# platform_designer_hps_system_hps_0_hps register map
Vendor: default_vendor.com; File version: 0.0
Registers are 32-bit, read-write, reset 0x0 unless marked. A register's access mark holds for its fields unless they carry their own. Offsets are from the block's base; [hi:lo] are bit positions; {n}, {i} and the like mark numbered series.

## rstmgr — Registers in the Reset Manager module
Base 0xFFD05000
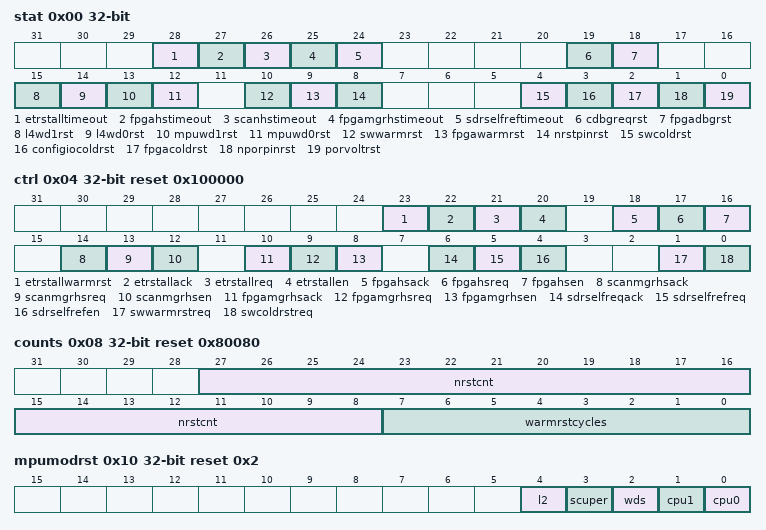
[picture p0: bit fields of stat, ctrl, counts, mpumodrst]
0x00 stat — The STAT register contains bits that indicate the reset source or a timeout event. For reset sources, a field is 1 if its associated reset requester caused the reset. For timeout events, a field is 1 if its associated timeout occured as part of a hardware sequenced warm/debug reset. Software clears bits by writing them with a value of 1. Writes to bits with a value of 0 are ignored. After a cold reset is complete, all bits are reset to their reset value except for the bit(s) that indicate the source of the cold reset. If multiple cold reset requests overlap with each other, the source de-asserts the request last will be logged. The other reset request source(s) de-assert the request in the same cycle will also be logged, the rest of the fields are reset to default value of 0. After a warm reset is complete, the bit(s) that indicate the source of the warm reset are set to 1. A warm reset doesn't clear any of the bits in the STAT register; these bits must be cleared by software writing the STAT register.
  [28] etrstalltimeout write-1-clears — A 1 indicates that Reset Manager's request to the ETR (Embedded Trace Router) to stall its AXI master port before starting a hardware sequenced warm reset timed-out and the Reset Manager had to proceed with the warm reset anyway.
  [27] fpgahstimeout write-1-clears — A 1 indicates that Reset Manager's handshake request to FPGA before starting a hardware sequenced warm reset timed-out and the Reset Manager had to proceed with the warm reset anyway.
  [26] scanhstimeout write-1-clears — A 1 indicates that Reset Manager's request to the SCAN manager to stop driving JTAG clock to FPGA CB before starting a hardware sequenced warm reset timed-out and the Reset Manager had to proceed with the warm reset anyway.
  [25] fpgamgrhstimeout write-1-clears — A 1 indicates that Reset Manager's request to the FPGA manager to stop driving configuration clock to FPGA CB before starting a hardware sequenced warm reset timed-out and the Reset Manager had to proceed with the warm reset anyway.
  [24] sdrselfreftimeout write-1-clears — A 1 indicates that Reset Manager's request to the SDRAM Controller Subsystem to put the SDRAM devices into self-refresh mode before starting a hardware sequenced warm reset timed-out and the Reset Manager had to proceed with the warm reset anyway.
  [19] cdbgreqrst write-1-clears — DAP triggered debug reset
  [18] fpgadbgrst write-1-clears — FPGA triggered debug reset (f2h_dbg_rst_req_n = 1)
  [15] l4wd1rst write-1-clears — L4 Watchdog 1 triggered a hardware sequenced warm reset
  [14] l4wd0rst write-1-clears — L4 Watchdog 0 triggered a hardware sequenced warm reset
  [13] mpuwd1rst write-1-clears — MPU Watchdog 1 triggered a hardware sequenced warm reset
  [12] mpuwd0rst write-1-clears — MPU Watchdog 0 triggered a hardware sequenced warm reset
  [10] swwarmrst write-1-clears — Software wrote CTRL.SWWARMRSTREQ to 1 and triggered a hardware sequenced warm reset
  [9] fpgawarmrst write-1-clears — FPGA core triggered a hardware sequenced warm reset (f2h_warm_rst_req_n = 1)
  [8] nrstpinrst write-1-clears — nRST pin triggered a hardware sequenced warm reset
  [4] swcoldrst write-1-clears — Software wrote CTRL.SWCOLDRSTREQ to 1 and triggered a cold reset
  [3] configiocoldrst write-1-clears — FPGA entered CONFIG_IO mode and a triggered a cold reset
  [2] fpgacoldrst write-1-clears — FPGA core triggered a cold reset (f2h_cold_rst_req_n = 1)
  [1] nporpinrst write-1-clears — nPOR pin triggered a cold reset (por_pin_req = 1)
  [0] porvoltrst write-1-clears — Built-in POR voltage detector triggered a cold reset (por_voltage_req = 1)
0x04 ctrl reset 0x100000 (reset mask 0xFFFBBBFF) — The CTRL register is used by software to control reset behavior.It includes fields for software to initiate the cold and warm reset, enable hardware handshake with other modules before warm reset, and perform software handshake. The software handshake sequence must match the hardware sequence. Software mustde-assert the handshake request after asserting warm reset and before de-assert the warm reset. Fields are only reset by a cold reset.
  [23] etrstallwarmrst write-1-clears — If a warm reset occurs and ETRSTALLEN is 1, hardware sets this bit to 1 to indicate that the stall of the ETR AXI master is pending. Hardware leaves the ETR stalled until software clears this field by writing it with 1. Software must only clear this field when it is ready to have the ETR AXI master start making AXI requests to write trace data.
  [22] etrstallack ro — This is the acknowlege for a ETR AXI master stall initiated by the ETRSTALLREQ field. A 1 indicates that the ETR has stalled its AXI master
  [21] etrstallreq — Software writes this field 1 to request to the ETR that it stalls its AXI master to the L3 Interconnect. Software waits for the ETRSTALLACK to be 1 and then writes this field to 0. Note that it is possible for the ETR to never assert ETRSTALLACK so software should timeout if ETRSTALLACK is never asserted.
  [20] etrstallen — This field controls whether the ETR is requested to idle its AXI master interface (i.e. finish outstanding transactions and not initiate any more) to the L3 Interconnect before a warm or debug reset. If set to 1, the Reset Manager makes a request to the ETR to stall its AXI master and waits for it to finish any outstanding AXI transactions before a warm reset of the L3 Interconnect or a debug reset of the ETR. This stalling is required because the debug logic (including the ETR) is reset on a debug reset and the ETR AXI master is connected to the L3 Interconnect which is reset on a warm reset and these resets can happen independently.
  [18] fpgahsack ro — This is the acknowlege (high active) that the FPGA handshake acknowledge has been received by Reset Manager.
  [17] fpgahsreq — Software writes this field 1 to initiate handshake request to FPGA . Software waits for the FPGAHSACK to be active and then writes this field to 0. Note that it is possible for the FPGA to never assert FPGAHSACK so software should timeout in this case.
  [16] fpgahsen — This field controls whether to perform handshake with FPGA before asserting warm reset. If set to 1, the Reset Manager makes a request to the FPGAbefore asserting warm reset signals. However if FPGA is already in warm reset state, the handshake is not performed. If set to 0, the handshake is not performed
  [14] scanmgrhsack ro — This is the acknowlege (high active) that the SCAN manager has successfully idled its output clocks.
  [13] scanmgrhsreq — Software writes this field 1 to request to the SCAN manager to idle its output clocks. Software waits for the SCANMGRHSACK to be 1 and then writes this field to 0. Note that it is possible for the Scan Manager to never assert SCANMGRHSACK (e.g. its input clock is disabled) so software should timeout in this case.
  [12] scanmgrhsen — Enables a handshake between the Reset Manager and Scan Manager before a warm reset. The handshake is used to warn the Scan Manager that a warm reset it coming so it can prepare for it. When the Scan Manager receives a warm reset handshake, the Scan Manager drives its output clocks to a quiescent state to avoid glitches. If set to 1, the Reset Manager makes a request to the Scan Managerbefore asserting warm reset signals. However if the Scan Manager is already in warm reset, the handshake is skipped. If set to 0, the handshake is skipped.
  [10] fpgamgrhsack ro — This is the acknowlege (high active) that the FPGA manager has successfully idled its output clock.
  [9] fpgamgrhsreq — Software writes this field 1 to request to the FPGA Manager to idle its output clock. Software waits for the FPGAMGRHSACK to be 1 and then writes this field to 0. Note that it is possible for the FPGA Manager to never assert FPGAMGRHSACK so software should timeout in this case.
  [8] fpgamgrhsen — Enables a handshake between the Reset Manager and FPGA Manager before a warm reset. The handshake is used to warn the FPGA Manager that a warm reset it coming so it can prepare for it. When the FPGA Manager receives a warm reset handshake, the FPGA Manager drives its output clock to a quiescent state to avoid glitches. If set to 1, the Manager makes a request to the FPGA Managerbefore asserting warm reset signals. However if the FPGA Manager is already in warm reset, the handshake is skipped. If set to 0, the handshake is skipped.
  [6] sdrselfreqack ro — This is the acknowlege for a SDRAM self-refresh mode request initiated by the SDRSELFREFREQ field. A 1 indicates that the SDRAM Controller Subsystem has put the SDRAM devices into self-refresh mode.
  [5] sdrselfrefreq — Software writes this field 1 to request to the SDRAM Controller Subsystem that it puts the SDRAM devices into self-refresh mode. This is done to preserve SDRAM contents across a software warm reset. Software waits for the SDRSELFREFACK to be 1 and then writes this field to 0. Note that it is possible for the SDRAM Controller Subsystem to never assert SDRSELFREFACK so software should timeout if SDRSELFREFACK is never asserted.
  [4] sdrselfrefen — This field controls whether the contents of SDRAM devices survive a hardware sequenced warm reset. If set to 1, the Reset Manager makes a request to the SDRAM Controller Subsystem to put the SDRAM devices into self-refresh mode before asserting warm reset signals. However, if SDRAM is already in warm reset, Handshake with SDRAM is not performed.
  [1] swwarmrstreq — This is a one-shot bit written by software to 1 to trigger a hardware sequenced warm reset. It always reads the value 0.
  [0] swcoldrstreq — This is a one-shot bit written by software to 1 to trigger a cold reset. It always reads the value 0.
0x08 counts reset 0x80080 — The COUNTS register is used by software to control reset behavior.It includes fields for software to control the behavior of the warm reset and nRST pin. Fields are only reset by a cold reset.
  [27:8] nrstcnt — The Reset Manager pulls down the nRST pin on a warm reset for the number of cycles specified in this register. A value of 0x0 prevents the Reset Manager from pulling down the nRST pin.
  [7:0] warmrstcycles — On a warm reset, the Reset Manager releases the reset to the Clock Manager, and then waits for the number of cycles specified in this register before releasing the rest of the hardware controlled resets. Value must be greater than 16.
0x10 mpumodrst reset 0x2 — The MPUMODRST register is used by software to trigger module resets (individual module reset signals). Software explicitly asserts and de-asserts module reset signals by writing bits in the appropriate *MODRST register. It is up to software to ensure module reset signals are asserted for the appropriate length of time and are de-asserted in the correct order. It is also up to software to not assert a module reset signal that would prevent software from de-asserting the module reset signal. For example, software should not assert the module reset to the CPU executing the software. Software writes a bit to 1 to assert the module reset signal and to 0 to de-assert the module reset signal. All fields except CPU1 are only reset by a cold reset. The CPU1 field is reset by a cold reset. The CPU1 field is also reset by a warm reset if not masked by the corresponding MPUWARMMASK field.
  [4] l2 — Resets L2 cache controller
  [3] scuper — Resets SCU and peripherals. Peripherals consist of the interrupt controller, global timer, both per-CPU private timers, and both per-CPU watchdogs (except for the Watchdog Reset Status registers).
  [2] wds — Resets both per-CPU Watchdog Reset Status registers in MPU.
  [1] cpu1 — Resets Cortex-A9 CPU1 in MPU. It is reset to 1 on a cold or warm reset. This holds CPU1 in reset until software is ready to release CPU1 from reset by writing 0 to this field. On single-core devices, writes to this field are ignored.On dual-core devices, writes to this field trigger the same sequence as writes to the CPU0 field (except the sequence is performed on CPU1).
  [0] cpu0 — Resets Cortex-A9 CPU0 in MPU. Whe software changes this field from 0 to 1, ittriggers the following sequence: 1. CPU0 reset is asserted. cpu0 clkoff is de-asserted 2. after 32 osc1_clk cycles, cpu0 clkoff is asserted. When software changes this field from 1 to 0, it triggers the following sequence: 1.CPU0 reset is de-asserted. 2. after 32 cycles, cpu0 clkoff is de-asserted. Software needs to wait for at least 64 osc1_clk cycles between each change of this field to keep the proper reset/clkoff sequence.
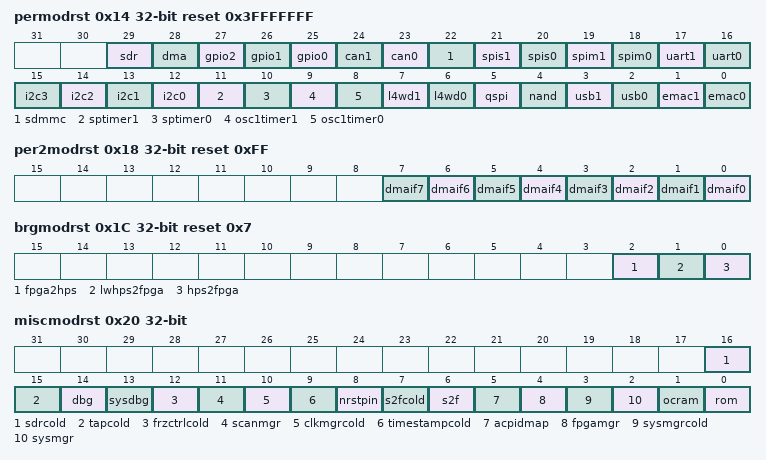
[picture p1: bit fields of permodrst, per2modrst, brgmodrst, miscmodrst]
0x14 permodrst reset 0x3FFFFFFF — The PERMODRST register is used by software to trigger module resets (individual module reset signals). Software explicitly asserts and de-asserts module reset signals by writing bits in the appropriate *MODRST register. It is up to software to ensure module reset signals are asserted for the appropriate length of time and are de-asserted in the correct order. It is also up to software to not assert a module reset signal that would prevent software from de-asserting the module reset signal. For example, software should not assert the module reset to the CPU executing the software. Software writes a bit to 1 to assert the module reset signal and to 0 to de-assert the module reset signal. All fields are reset by a cold reset.All fields are also reset by a warm reset if not masked by the corresponding PERWARMMASK field. The reset value of all fields is 1. This holds the corresponding module in reset until software is ready to release the module from reset by writing 0 to its field.
  [29] sdr — Resets SDRAM Controller Subsystem affected by a warm or cold reset.
  [28] dma — Resets DMA controller
  [27] gpio2 — Resets GPIO2
  [26] gpio1 — Resets GPIO1
  [25] gpio0 — Resets GPIO0
  [24] can1 — Resets CAN1 controller. Writes to this field on devices not containing CAN controllers will be ignored.
  [23] can0 — Resets CAN0 controller. Writes to this field on devices not containing CAN controllers will be ignored.
  [22] sdmmc — Resets SD/MMC controller
  [21] spis1 — Resets SPIS1 controller
  [20] spis0 — Resets SPIS0 controller
  [19] spim1 — Resets SPIM1 controller
  [18] spim0 — Resets SPIM0 controller
  [17] uart1 — Resets UART1
  [16] uart0 — Resets UART0
  [n+12] i2c{n} (n=0..3) — Resets I2C{n} controller
  [11] sptimer1 — Resets SP timer 1 connected to L4
  [10] sptimer0 — Resets SP timer 0 connected to L4
  [9] osc1timer1 — Resets OSC1 timer 1 connected to L4
  [8] osc1timer0 — Resets OSC1 timer 0 connected to L4
  [7] l4wd1 — Resets watchdog 1 connected to L4
  [6] l4wd0 — Resets watchdog 0 connected to L4
  [5] qspi — Resets QSPI flash controller
  [4] nand — Resets NAND flash controller
  [3] usb1 — Resets USB1
  [2] usb0 — Resets USB0
  [1] emac1 — Resets EMAC1
  [0] emac0 — Resets EMAC0
0x18 per2modrst reset 0xFF — The PER2MODRST register is used by software to trigger module resets (individual module reset signals). Software explicitly asserts and de-asserts module reset signals by writing bits in the appropriate *MODRST register. It is up to software to ensure module reset signals are asserted for the appropriate length of time and are de-asserted in the correct order. It is also up to software to not assert a module reset signal that would prevent software from de-asserting the module reset signal. For example, software should not assert the module reset to the CPU executing the software. Software writes a bit to 1 to assert the module reset signal and to 0 to de-assert the module reset signal. All fields are reset by a cold reset.All fields are also reset by a warm reset if not masked by the corresponding PERWARMMASK field. The reset value of all fields is 1. This holds the corresponding module in reset until software is ready to release the module from reset by writing 0 to its field.
  [n] dmaif{n} (n=0..7) — Resets DMA channel {n} interface adapter between FPGA Fabric and HPS DMA Controller
0x1C brgmodrst reset 0x7 — The BRGMODRST register is used by software to trigger module resets (individual module reset signals). Software explicitly asserts and de-asserts module reset signals by writing bits in the appropriate *MODRST register. It is up to software to ensure module reset signals are asserted for the appropriate length of time and are de-asserted in the correct order. It is also up to software to not assert a module reset signal that would prevent software from de-asserting the module reset signal. For example, software should not assert the module reset to the CPU executing the software. Software writes a bit to 1 to assert the module reset signal and to 0 to de-assert the module reset signal. All fields are reset by a cold reset.All fields are also reset by a warm reset if not masked by the corresponding BRGWARMMASK field. The reset value of all fields is 1. This holds the corresponding module in reset until software is ready to release the module from reset by writing 0 to its field.
  [2] fpga2hps — Resets FPGA2HPS Bridge
  [1] lwhps2fpga — Resets LWHPS2FPGA Bridge
  [0] hps2fpga — Resets HPS2FPGA Bridge
0x20 miscmodrst — The MISCMODRST register is used by software to trigger module resets (individual module reset signals). Software explicitly asserts and de-asserts module reset signals by writing bits in the appropriate *MODRST register. It is up to software to ensure module reset signals are asserted for the appropriate length of time and are de-asserted in the correct order. It is also up to software to not assert a module reset signal that would prevent software from de-asserting the module reset signal. For example, software should not assert the module reset to the CPU executing the software. Software writes a bit to 1 to assert the module reset signal and to 0 to de-assert the module reset signal. All fields are only reset by a cold reset
  [16] sdrcold — Resets logic in SDRAM Controller Subsystem affected only by a cold reset.
  [15] tapcold — Resets portion of DAP JTAG TAP controller no reset by a debug probe reset (i.e. nTRST pin). Cold reset only.
  [14] dbg — Resets logic located only in the debug domain.
  [13] sysdbg — Resets logic that spans the system and debug domains.
  [12] frzctrlcold — Resets Freeze Controller in System Manager (cold reset only)
  [11] scanmgr — Resets Scan Manager
  [10] clkmgrcold — Resets Clock Manager (cold reset only)
  [9] timestampcold — Resets debug timestamp to 0 (cold reset only)
  [8] nrstpin — Pulls nRST pin low
  [7] s2fcold — Resets logic in FPGA core that is only reset by a cold reset (ignores warm reset) (h2f_cold_rst_n = 1)
  [6] s2f — Resets logic in FPGA core that doesn't differentiate between HPS cold and warm resets (h2f_rst_n = 1)
  [5] acpidmap — Resets ACP ID Mapper
  [4] fpgamgr — Resets FPGA Manager
  [3] sysmgrcold — Resets logic in System Manager that is only reset by a cold reset (ignores warm reset)
  [2] sysmgr — Resets logic in System Manager that doesn't differentiate between cold and warm resets
  [1] ocram — Resets On-chip RAM
  [0] rom — Resets Boot ROM
